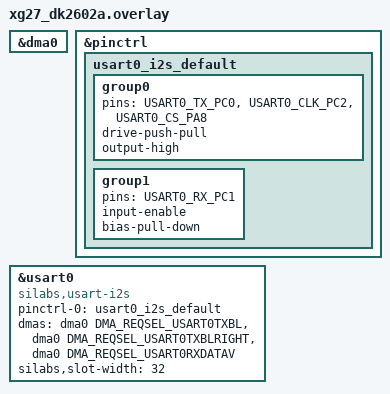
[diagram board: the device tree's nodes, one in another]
/*
 * SPDX-FileCopyrightText: Copyright (c) 2026 Silicon Laboratories Inc.
 * SPDX-License-Identifier: Apache-2.0
 *
 * xG27-DK2602A: USART0 I2S for samples/drivers/i2s/echo (mic + amp).
 * PC0 TX, PC1 RX, PC2 BCLK, PA8 WS. Delete on-board MX25 on USART0.
 */

#include <zephyr/dt-bindings/pinctrl/silabs/xg27-pinctrl.h>
#include <zephyr/dt-bindings/dma/silabs/xg27-dma.h>

&dma0 {
	status = "okay";
};

&pinctrl {
	usart0_i2s_default: usart0_i2s_default {
		group0 {
			pins = <USART0_TX_PC0>, <USART0_CLK_PC2>, <USART0_CS_PA8>;
			drive-push-pull;
			output-high;
		};

		group1 {
			pins = <USART0_RX_PC1>;
			input-enable;
			bias-pull-down;
		};
	};
};

/delete-node/ &mx25r80;

i2s_rxtx: &usart0 {
	compatible = "silabs,usart-i2s";
	/delete-property/ cs-gpios;
	/delete-property/ clock-frequency;
	#address-cells = <1>;
	#size-cells = <0>;
	pinctrl-0 = <&usart0_i2s_default>;
	pinctrl-names = "default";
	dmas = <&dma0 DMA_REQSEL_USART0TXBL>,
	       <&dma0 DMA_REQSEL_USART0TXBLRIGHT>,
	       <&dma0 DMA_REQSEL_USART0RXDATAV>;
	dma-names = "txbl", "txblright", "rxdatav";
	silabs,slot-width = <32>;
	status = "okay";
};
